# qmss_config register map
Vendor: Texas Instruments
Peripheral module from a debugger description file (folder Keystone2).
Registers are 32-bit, read-write, no defined reset value unless marked. A register's access mark holds for its fields unless they carry their own. Offsets are as the file gives them; lines under a group give offsets from that group; [hi:lo] are bit positions; {n}, {i} and the like mark numbered series; 'fields as' and 'values as' point back to an identical list; <NAME> marks a mode.

## QM_2_CFG
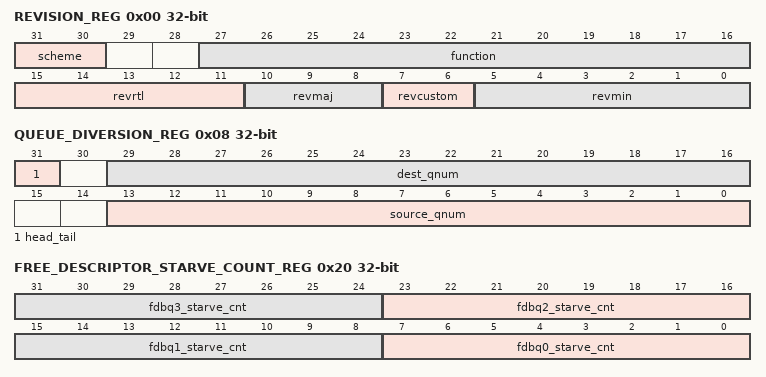
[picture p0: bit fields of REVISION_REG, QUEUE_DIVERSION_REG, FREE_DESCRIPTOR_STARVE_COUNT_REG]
0x00 REVISION_REG ro
  [31:30] scheme — Scheme that this register is compliant with
  [27:16] function
  [15:11] revrtl — RTL revision
  [10:8] revmaj — Major revision
  [7:6] revcustom — Custom revision
  [5:0] revmin — Minor revision
0x08 QUEUE_DIVERSION_REG wo
  [31] head_tail — Indicates whether queue contents should be merged on to head or tail of destination queue. Clear this field for head and set for tail.
  [29:16] dest_qnum — Destination queue number
  [13:0] source_qnum — Source queue number
0x0C LINKING_RAM_REGION_0_BASE_ADDRESS_REG
  [31:0] region0_base — This field stores the base address for the first region of the linking RAM. This may be anywhere in 32-bit address space but would be typically located in on-chip memory.
0x10 LINKING_RAM_REGION_0_SIZE_REG
  [18:0] region0_size — This field indicates the number of entries that are contained in the linking RAM region 0
0x14 LINKING_RAM_REGION_1_BASE_ADDRESS_REG
  [31:0] region1_base — This field stores the base address for the first region of the linking RAM. This may be anywhere in 32-bit address space but would be typically located in on-chip memory.
0x20 FREE_DESCRIPTOR_STARVE_COUNT_REG ro — (1 of 16, stride 4)
  [8n+7:8n] fdbq{n}_starve_cnt (n=0..3) — This field increments each time the Free Descriptor/Buffer Queue \[N mod 4\]=={n} is read while it is empty. This field is cleared when read.
